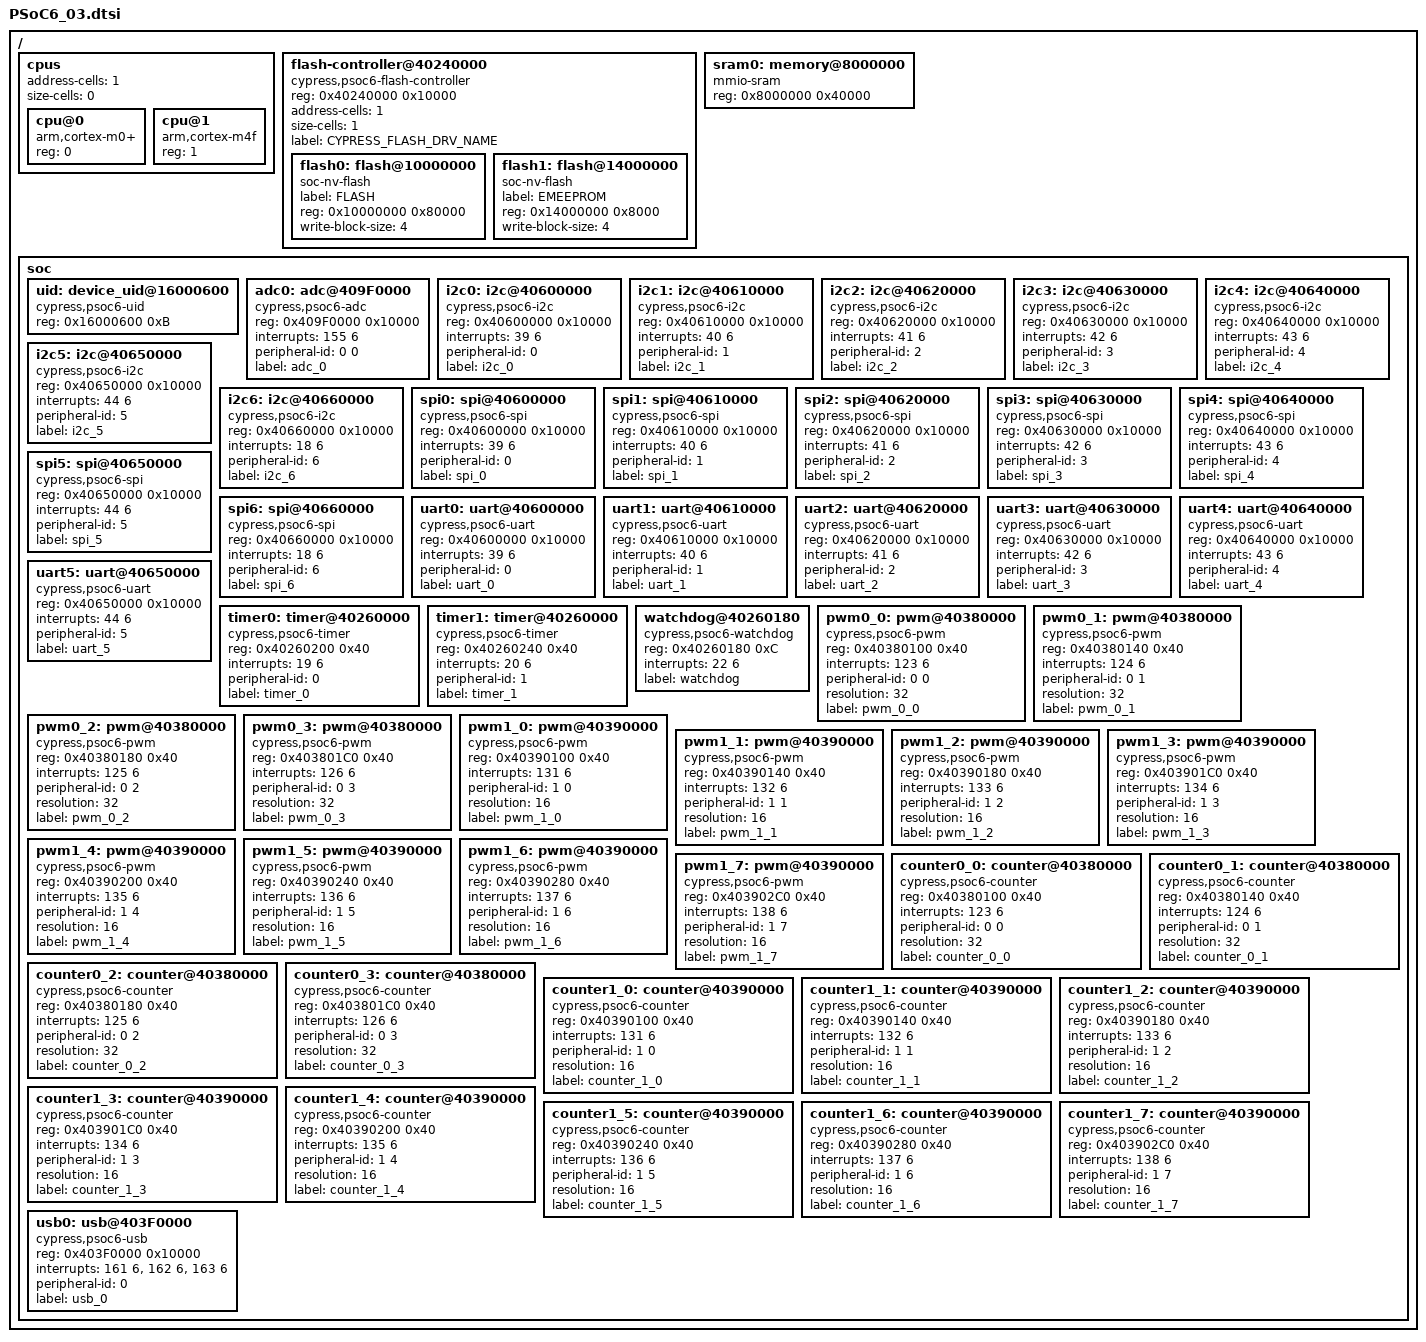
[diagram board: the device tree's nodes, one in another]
/*
 * Copyright (c) 2021, Cypress Semiconductor
 * 
 * SPDX-License-Identifier: Apache-2.0
 */

#include <mem.h>

/ {
    cpus {
        # address-cells = <1>;
        # size-cells = <0>;

        cpu@0 {
            device_type = "cpu";
            compatible = "arm,cortex-m0+";
            reg = <0>;
        };
        cpu@1 {
            device_type = "cpu";
            compatible = "arm,cortex-m4f";
            reg = <1>;
        };
    };
    flash-controller@40240000 {
        compatible = "cypress,psoc6-flash-controller";
        reg = < 0x40240000 0x10000 >;
        # address-cells = <1>;
        # size-cells = <1>;
        label = "CYPRESS_FLASH_DRV_NAME";

        flash0: flash@10000000 {
            compatible = "soc-nv-flash"; 
            label = "FLASH"; 
            reg = <0x10000000 0x80000>;
            write-block-size = <4>;
        };
        flash1: flash@14000000 {
            compatible = "soc-nv-flash";
            label = "EMEEPROM"; 
            reg = <0x14000000 0x8000>;
            write-block-size = <4>;
        };
    };
    sram0: memory@8000000 {
        compatible = "mmio-sram"; 
        reg = <0x8000000 0x40000>;
    };

    soc {
        uid: device_uid@16000600 {
            compatible = "cypress,psoc6-uid";
            reg = <0x16000600 0xB>;
            status = "okay";
        };

        adc0: adc@409F0000 {
            compatible = "cypress,psoc6-adc";
            reg = <0x409F0000 0x10000>;
            interrupts = <155 6>;
            peripheral-id = <0 0>;
            status = "okay";
            label = "adc_0";
        };

        i2c0: i2c@40600000 {
            compatible = "cypress,psoc6-i2c";
            reg = <0x40600000 0x10000>;
            interrupts = <39 6>;
            peripheral-id = <0>;
            status = "okay";
            label = "i2c_0";
        };
        i2c1: i2c@40610000 {
            compatible = "cypress,psoc6-i2c";
            reg = <0x40610000 0x10000>;
            interrupts = <40 6>;
            peripheral-id = <1>;
            status = "okay";
            label = "i2c_1";
        };
        i2c2: i2c@40620000 {
            compatible = "cypress,psoc6-i2c";
            reg = <0x40620000 0x10000>;
            interrupts = <41 6>;
            peripheral-id = <2>;
            status = "okay";
            label = "i2c_2";
        };
        i2c3: i2c@40630000 {
            compatible = "cypress,psoc6-i2c";
            reg = <0x40630000 0x10000>;
            interrupts = <42 6>;
            peripheral-id = <3>;
            status = "okay";
            label = "i2c_3";
        };
        i2c4: i2c@40640000 {
            compatible = "cypress,psoc6-i2c";
            reg = <0x40640000 0x10000>;
            interrupts = <43 6>;
            peripheral-id = <4>;
            status = "okay";
            label = "i2c_4";
        };
        i2c5: i2c@40650000 {
            compatible = "cypress,psoc6-i2c";
            reg = <0x40650000 0x10000>;
            interrupts = <44 6>;
            peripheral-id = <5>;
            status = "okay";
            label = "i2c_5";
        };
        i2c6: i2c@40660000 {
            compatible = "cypress,psoc6-i2c";
            reg = <0x40660000 0x10000>;
            interrupts = <18 6>;
            peripheral-id = <6>;
            status = "okay";
            label = "i2c_6";
        };

        spi0: spi@40600000 {
            compatible = "cypress,psoc6-spi";
            reg = <0x40600000 0x10000>;
            interrupts = <39 6>;
            peripheral-id = <0>;
            status = "okay";
            label = "spi_0";
        };
        spi1: spi@40610000 {
            compatible = "cypress,psoc6-spi";
            reg = <0x40610000 0x10000>;
            interrupts = <40 6>;
            peripheral-id = <1>;
            status = "okay";
            label = "spi_1";
        };
        spi2: spi@40620000 {
            compatible = "cypress,psoc6-spi";
            reg = <0x40620000 0x10000>;
            interrupts = <41 6>;
            peripheral-id = <2>;
            status = "okay";
            label = "spi_2";
        };
        spi3: spi@40630000 {
            compatible = "cypress,psoc6-spi";
            reg = <0x40630000 0x10000>;
            interrupts = <42 6>;
            peripheral-id = <3>;
            status = "okay";
            label = "spi_3";
        };
        spi4: spi@40640000 {
            compatible = "cypress,psoc6-spi";
            reg = <0x40640000 0x10000>;
            interrupts = <43 6>;
            peripheral-id = <4>;
            status = "okay";
            label = "spi_4";
        };
        spi5: spi@40650000 {
            compatible = "cypress,psoc6-spi";
            reg = <0x40650000 0x10000>;
            interrupts = <44 6>;
            peripheral-id = <5>;
            status = "okay";
            label = "spi_5";
        };
        spi6: spi@40660000 {
            compatible = "cypress,psoc6-spi";
            reg = <0x40660000 0x10000>;
            interrupts = <18 6>;
            peripheral-id = <6>;
            status = "okay";
            label = "spi_6";
        };

        uart0: uart@40600000 {
            compatible = "cypress,psoc6-uart";
            reg = <0x40600000 0x10000>;
            interrupts = <39 6>;
            peripheral-id = <0>;
            status = "okay";
            label = "uart_0";
        };
        uart1: uart@40610000 {
            compatible = "cypress,psoc6-uart";
            reg = <0x40610000 0x10000>;
            interrupts = <40 6>;
            peripheral-id = <1>;
            status = "okay";
            label = "uart_1";
        };
        uart2: uart@40620000 {
            compatible = "cypress,psoc6-uart";
            reg = <0x40620000 0x10000>;
            interrupts = <41 6>;
            peripheral-id = <2>;
            status = "okay";
            label = "uart_2";
        };
        uart3: uart@40630000 {
            compatible = "cypress,psoc6-uart";
            reg = <0x40630000 0x10000>;
            interrupts = <42 6>;
            peripheral-id = <3>;
            status = "okay";
            label = "uart_3";
        };
        uart4: uart@40640000 {
            compatible = "cypress,psoc6-uart";
            reg = <0x40640000 0x10000>;
            interrupts = <43 6>;
            peripheral-id = <4>;
            status = "okay";
            label = "uart_4";
        };
        uart5: uart@40650000 {
            compatible = "cypress,psoc6-uart";
            reg = <0x40650000 0x10000>;
            interrupts = <44 6>;
            peripheral-id = <5>;
            status = "okay";
            label = "uart_5";
        };

        timer0: timer@40260000 {
            compatible = "cypress,psoc6-timer";
            reg = <0x40260200 0x40>;
            interrupts = <19 6>;
            peripheral-id = <0>;
            status = "okay";
            label = "timer_0";
        };
        timer1: timer@40260000 {
            compatible = "cypress,psoc6-timer";
            reg = <0x40260240 0x40>;
            interrupts = <20 6>;
            peripheral-id = <1>;
            status = "okay";
            label = "timer_1";
        };

        watchdog@40260180 {
            compatible = "cypress,psoc6-watchdog";
            reg = <0x40260180 0xC>;
            interrupts = <22 6>;
            status = "okay";
            label = "watchdog";
        };

        pwm0_0: pwm@40380000 {
            compatible = "cypress,psoc6-pwm";
            reg = <0x40380100 0x40>;
            interrupts = <123 6>;
            peripheral-id = <0 0>;
            resolution = <32>;
            status = "okay";
            label = "pwm_0_0";
        };
        pwm0_1: pwm@40380000 {
            compatible = "cypress,psoc6-pwm";
            reg = <0x40380140 0x40>;
            interrupts = <124 6>;
            peripheral-id = <0 1>;
            resolution = <32>;
            status = "okay";
            label = "pwm_0_1";
        };
        pwm0_2: pwm@40380000 {
            compatible = "cypress,psoc6-pwm";
            reg = <0x40380180 0x40>;
            interrupts = <125 6>;
            peripheral-id = <0 2>;
            resolution = <32>;
            status = "okay";
            label = "pwm_0_2";
        };
        pwm0_3: pwm@40380000 {
            compatible = "cypress,psoc6-pwm";
            reg = <0x403801C0 0x40>;
            interrupts = <126 6>;
            peripheral-id = <0 3>;
            resolution = <32>;
            status = "okay";
            label = "pwm_0_3";
        };
        pwm1_0: pwm@40390000 {
            compatible = "cypress,psoc6-pwm";
            reg = <0x40390100 0x40>;
            interrupts = <131 6>;
            peripheral-id = <1 0>;
            resolution = <16>;
            status = "okay";
            label = "pwm_1_0";
        };
        pwm1_1: pwm@40390000 {
            compatible = "cypress,psoc6-pwm";
            reg = <0x40390140 0x40>;
            interrupts = <132 6>;
            peripheral-id = <1 1>;
            resolution = <16>;
            status = "okay";
            label = "pwm_1_1";
        };
        pwm1_2: pwm@40390000 {
            compatible = "cypress,psoc6-pwm";
            reg = <0x40390180 0x40>;
            interrupts = <133 6>;
            peripheral-id = <1 2>;
            resolution = <16>;
            status = "okay";
            label = "pwm_1_2";
        };
        pwm1_3: pwm@40390000 {
            compatible = "cypress,psoc6-pwm";
            reg = <0x403901C0 0x40>;
            interrupts = <134 6>;
            peripheral-id = <1 3>;
            resolution = <16>;
            status = "okay";
            label = "pwm_1_3";
        };
        pwm1_4: pwm@40390000 {
            compatible = "cypress,psoc6-pwm";
            reg = <0x40390200 0x40>;
            interrupts = <135 6>;
            peripheral-id = <1 4>;
            resolution = <16>;
            status = "okay";
            label = "pwm_1_4";
        };
        pwm1_5: pwm@40390000 {
            compatible = "cypress,psoc6-pwm";
            reg = <0x40390240 0x40>;
            interrupts = <136 6>;
            peripheral-id = <1 5>;
            resolution = <16>;
            status = "okay";
            label = "pwm_1_5";
        };
        pwm1_6: pwm@40390000 {
            compatible = "cypress,psoc6-pwm";
            reg = <0x40390280 0x40>;
            interrupts = <137 6>;
            peripheral-id = <1 6>;
            resolution = <16>;
            status = "okay";
            label = "pwm_1_6";
        };
        pwm1_7: pwm@40390000 {
            compatible = "cypress,psoc6-pwm";
            reg = <0x403902C0 0x40>;
            interrupts = <138 6>;
            peripheral-id = <1 7>;
            resolution = <16>;
            status = "okay";
            label = "pwm_1_7";
        };

        counter0_0: counter@40380000 {
            compatible = "cypress,psoc6-counter";
            reg = <0x40380100 0x40>;
            interrupts = <123 6>;
            peripheral-id = <0 0>;
            resolution = <32>;
            status = "okay";
            label = "counter_0_0";
        };
        counter0_1: counter@40380000 {
            compatible = "cypress,psoc6-counter";
            reg = <0x40380140 0x40>;
            interrupts = <124 6>;
            peripheral-id = <0 1>;
            resolution = <32>;
            status = "okay";
            label = "counter_0_1";
        };
        counter0_2: counter@40380000 {
            compatible = "cypress,psoc6-counter";
            reg = <0x40380180 0x40>;
            interrupts = <125 6>;
            peripheral-id = <0 2>;
            resolution = <32>;
            status = "okay";
            label = "counter_0_2";
        };
        counter0_3: counter@40380000 {
            compatible = "cypress,psoc6-counter";
            reg = <0x403801C0 0x40>;
            interrupts = <126 6>;
            peripheral-id = <0 3>;
            resolution = <32>;
            status = "okay";
            label = "counter_0_3";
        };
        counter1_0: counter@40390000 {
            compatible = "cypress,psoc6-counter";
            reg = <0x40390100 0x40>;
            interrupts = <131 6>;
            peripheral-id = <1 0>;
            resolution = <16>;
            status = "okay";
            label = "counter_1_0";
        };
        counter1_1: counter@40390000 {
            compatible = "cypress,psoc6-counter";
            reg = <0x40390140 0x40>;
            interrupts = <132 6>;
            peripheral-id = <1 1>;
            resolution = <16>;
            status = "okay";
            label = "counter_1_1";
        };
        counter1_2: counter@40390000 {
            compatible = "cypress,psoc6-counter";
            reg = <0x40390180 0x40>;
            interrupts = <133 6>;
            peripheral-id = <1 2>;
            resolution = <16>;
            status = "okay";
            label = "counter_1_2";
        };
        counter1_3: counter@40390000 {
            compatible = "cypress,psoc6-counter";
            reg = <0x403901C0 0x40>;
            interrupts = <134 6>;
            peripheral-id = <1 3>;
            resolution = <16>;
            status = "okay";
            label = "counter_1_3";
        };
        counter1_4: counter@40390000 {
            compatible = "cypress,psoc6-counter";
            reg = <0x40390200 0x40>;
            interrupts = <135 6>;
            peripheral-id = <1 4>;
            resolution = <16>;
            status = "okay";
            label = "counter_1_4";
        };
        counter1_5: counter@40390000 {
            compatible = "cypress,psoc6-counter";
            reg = <0x40390240 0x40>;
            interrupts = <136 6>;
            peripheral-id = <1 5>;
            resolution = <16>;
            status = "okay";
            label = "counter_1_5";
        };
        counter1_6: counter@40390000 {
            compatible = "cypress,psoc6-counter";
            reg = <0x40390280 0x40>;
            interrupts = <137 6>;
            peripheral-id = <1 6>;
            resolution = <16>;
            status = "okay";
            label = "counter_1_6";
        };
        counter1_7: counter@40390000 {
            compatible = "cypress,psoc6-counter";
            reg = <0x403902C0 0x40>;
            interrupts = <138 6>;
            peripheral-id = <1 7>;
            resolution = <16>;
            status = "okay";
            label = "counter_1_7";
        };

        usb0: usb@403F0000 {
            compatible = "cypress,psoc6-usb";
            reg = <0x403F0000 0x10000>;
            interrupts = <161 6 /* Hi */>,
                         <162 6 /* Med */>,
                         <163 6 /* Lo */>;
            peripheral-id = <0>;
            status = "okay";
            label = "usb_0";
        };

    };
};
